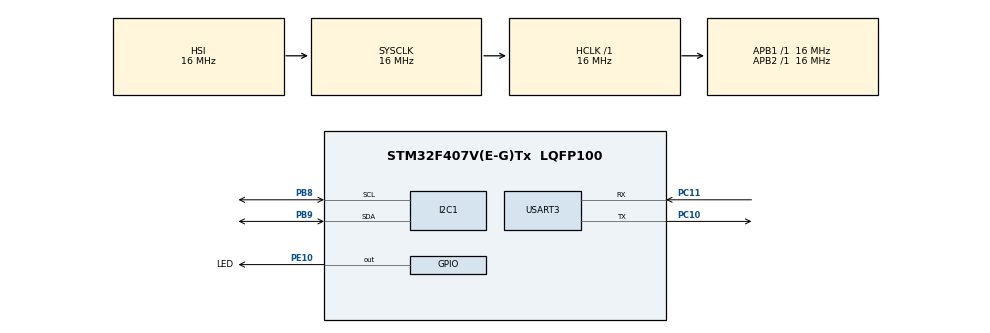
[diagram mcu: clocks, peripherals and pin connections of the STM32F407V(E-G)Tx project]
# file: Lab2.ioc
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Mcu.Family=STM32F4
Mcu.Name=STM32F407V(E-G)Tx
Mcu.Package=LQFP100
NVIC.PriorityGroup=NVIC_PRIORITYGROUP_4
PB8.Mode=I2C
PB8.Signal=I2C1_SCL
PB9.Mode=I2C
PB9.Signal=I2C1_SDA
PC10.Mode=Asynchronous
PC10.Signal=USART3_TX
PC11.Mode=Asynchronous
PC11.Signal=USART3_RX
PE10.GPIO_Label=LED
PE10.Signal=GPIO_Output
ProjectManager.HeapSize=0x200
ProjectManager.StackSize=0x400
ProjectManager.TargetToolchain=STM32CubeIDE
RCC.AHBFreq_Value=16000000
RCC.APB1Freq_Value=16000000
RCC.APB2Freq_Value=16000000
RCC.CortexFreq_Value=16000000
RCC.HSE_VALUE=25000000
RCC.HSI_VALUE=16000000
RCC.LSE_VALUE=32768
RCC.SYSCLKFreq_VALUE=16000000
RCC.VCOOutputFreq_Value=192000000
USART3.VirtualMode=VM_ASYNC
board=custom

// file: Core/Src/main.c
/* USER CODE BEGIN Header */
/**
  ******************************************************************************
  * @file           : main.c
  * @brief          : Main program body
  ******************************************************************************
  * @attention
  *
  * Copyright (c) 2022 STMicroelectronics.
  * All rights reserved.
  *
  * This software is licensed under terms that can be found in the LICENSE file
  * in the root directory of this software component.
  * If no LICENSE file comes with this software, it is provided AS-IS.
  *
  ******************************************************************************
  */
/* USER CODE END Header */
#include "main.h"
#include "math.h"
/* USER CODE BEGIN Includes */
#include "ICM20948.h"
/* USER CODE END Includes */

I2C_HandleTypeDef hi2c1;

UART_HandleTypeDef huart3;

void SystemClock_Config(void);
static void MX_GPIO_Init(void);
static void MX_USART3_UART_Init(void);
static void MX_I2C1_Init(void);

int main(void)
{

  /* MCU Configuration--------------------------------------------------------*/

  /* Reset of all peripherals, Initializes the Flash interface and the Systick. */
  HAL_Init();

  /* USER CODE BEGIN Init */
	ICM20948 imu;
	char sbuf2[20];
	char sbuf[3][6];
  /* USER CODE END Init */

  /* Configure the system clock */
  SystemClock_Config();

  /* Initialize all configured peripherals */
  MX_GPIO_Init();
  MX_USART3_UART_Init();
  MX_I2C1_Init();
  /* USER CODE BEGIN 2 */
  uint8_t i;
  uint8_t status = IMU_Initialise(&imu,&hi2c1,&huart3);
  float aroll,apitch,groll=0,gpitch=0,compitch=0,comroll=0;

  uint32_t miliNew;
  uint32_t miliOld=HAL_GetTick();
  uint32_t dt=0;
  /* USER CODE END 2 */
  /* Infinite loop */
  /* USER CODE BEGIN WHILE */

  while (1)
  {

      miliNew = HAL_GetTick();
      dt=miliNew-miliOld;
	  HAL_StatusTypeDef accelstatus = IMU_AccelRead(&imu);
	  HAL_StatusTypeDef gyrostatus = IMU_GyroRead(&imu);
	  /*for ( i= 0; i < 3; i++) //raw accel
	  {
		  sprintf(sbuf[i],"%5.2f ",imu.acc[i]);
		  HAL_UART_Transmit(&huart3, sbuf[i], 6, HAL_MAX_DELAY);
	  }

	  for ( i= 0; i < 3; i++) //raw gyro
	  	  {
	  		  sprintf(sbuf[i],"%5.2f ",imu.gyro[i]);
	  		  HAL_UART_Transmit(&huart3, sbuf[i], 6, HAL_MAX_DELAY);
	  	  }*///teta/sec

	  aroll = atan2(imu.acc[1],imu.acc[2])*180/M_PI;
	  sprintf(sbuf2,"%5.2f ",aroll);
	  HAL_UART_Transmit(&huart3, sbuf2, 6, HAL_MAX_DELAY);

	  groll=(groll+imu.gyro[0]*dt*0.001);//absolute angle//relative angle
	  sprintf(sbuf2,"%5.2f ",groll);
	  HAL_UART_Transmit(&huart3, sbuf2, 6, HAL_MAX_DELAY);

	  comroll=(0.1*aroll)+(0.9*(comroll+imu.gyro[0]*dt*0.001));
	  sprintf(sbuf2,"%5.2f ",comroll);
	  HAL_UART_Transmit(&huart3, sbuf2, 6, HAL_MAX_DELAY);

	  apitch = -1*atan2(imu.acc[0],imu.acc[2]) *180/M_PI;
	  sprintf(sbuf2,"%5.2f ",apitch);
	  HAL_UART_Transmit(&huart3, sbuf2, 6, HAL_MAX_DELAY);

	  gpitch=(gpitch+imu.gyro[1]*dt*0.001);
	  sprintf(sbuf2,"%5.2f ",gpitch*-1);
	  HAL_UART_Transmit(&huart3, sbuf2, 6, HAL_MAX_DELAY);

	  compitch=(0.1*apitch)+(0.9*(compitch+imu.gyro[1]*dt*0.001));
	  sprintf(sbuf2,"%5.2f ",compitch);
	  HAL_UART_Transmit(&huart3, sbuf2, 6, HAL_MAX_DELAY);

	  sprintf(sbuf2,"\r\n");
	  HAL_UART_Transmit(&huart3, sbuf2, 2, HAL_MAX_DELAY);

	  miliOld= miliNew;
  }
  /* USER CODE END 3 */
}

void SystemClock_Config(void)
{
  RCC_OscInitTypeDef RCC_OscInitStruct = {0};
  RCC_ClkInitTypeDef RCC_ClkInitStruct = {0};

  /** Configure the main internal regulator output voltage
  */
  __HAL_RCC_PWR_CLK_ENABLE();
  __HAL_PWR_VOLTAGESCALING_CONFIG(PWR_REGULATOR_VOLTAGE_SCALE1);

  /** Initializes the RCC Oscillators according to the specified parameters
  * in the RCC_OscInitTypeDef structure.
  */
  RCC_OscInitStruct.OscillatorType = RCC_OSCILLATORTYPE_HSI;
  RCC_OscInitStruct.HSIState = RCC_HSI_ON;
  RCC_OscInitStruct.HSICalibrationValue = RCC_HSICALIBRATION_DEFAULT;
  RCC_OscInitStruct.PLL.PLLState = RCC_PLL_NONE;
  if (HAL_RCC_OscConfig(&RCC_OscInitStruct) != HAL_OK)
  {
    Error_Handler();
  }

  /** Initializes the CPU, AHB and APB buses clocks
  */
  RCC_ClkInitStruct.ClockType = RCC_CLOCKTYPE_HCLK|RCC_CLOCKTYPE_SYSCLK
                              |RCC_CLOCKTYPE_PCLK1|RCC_CLOCKTYPE_PCLK2;
  RCC_ClkInitStruct.SYSCLKSource = RCC_SYSCLKSOURCE_HSI;
  RCC_ClkInitStruct.AHBCLKDivider = RCC_SYSCLK_DIV1;
  RCC_ClkInitStruct.APB1CLKDivider = RCC_HCLK_DIV1;
  RCC_ClkInitStruct.APB2CLKDivider = RCC_HCLK_DIV1;

  if (HAL_RCC_ClockConfig(&RCC_ClkInitStruct, FLASH_LATENCY_0) != HAL_OK)
  {
    Error_Handler();
  }
}

static void MX_I2C1_Init(void)
{

  hi2c1.Instance = I2C1;
  hi2c1.Init.ClockSpeed = 100000;
  hi2c1.Init.DutyCycle = I2C_DUTYCYCLE_2;
  hi2c1.Init.OwnAddress1 = 0;
  hi2c1.Init.AddressingMode = I2C_ADDRESSINGMODE_7BIT;
  hi2c1.Init.DualAddressMode = I2C_DUALADDRESS_DISABLE;
  hi2c1.Init.OwnAddress2 = 0;
  hi2c1.Init.GeneralCallMode = I2C_GENERALCALL_DISABLE;
  hi2c1.Init.NoStretchMode = I2C_NOSTRETCH_DISABLE;
  if (HAL_I2C_Init(&hi2c1) != HAL_OK)
  {
    Error_Handler();
  }

}

static void MX_USART3_UART_Init(void)
{

  huart3.Instance = USART3;
  huart3.Init.BaudRate = 115200;
  huart3.Init.WordLength = UART_WORDLENGTH_8B;
  huart3.Init.StopBits = UART_STOPBITS_1;
  huart3.Init.Parity = UART_PARITY_NONE;
  huart3.Init.Mode = UART_MODE_TX_RX;
  huart3.Init.HwFlowCtl = UART_HWCONTROL_NONE;
  huart3.Init.OverSampling = UART_OVERSAMPLING_16;
  if (HAL_UART_Init(&huart3) != HAL_OK)
  {
    Error_Handler();
  }

}

static void MX_GPIO_Init(void)
{
  GPIO_InitTypeDef GPIO_InitStruct = {0};

  /* GPIO Ports Clock Enable */
  __HAL_RCC_GPIOE_CLK_ENABLE();
  __HAL_RCC_GPIOB_CLK_ENABLE();
  __HAL_RCC_GPIOA_CLK_ENABLE();
  __HAL_RCC_GPIOC_CLK_ENABLE();

  /*Configure GPIO pin Output Level */

  /*Configure GPIO pin Output Level */

  /*Configure GPIO pins : SCLK_Pin SDIN_Pin RESET__Pin D_C__Pin
                           LED3_Pin */

}

void Error_Handler(void)
{
  __disable_irq();
  while (1)
  {
  }
}
